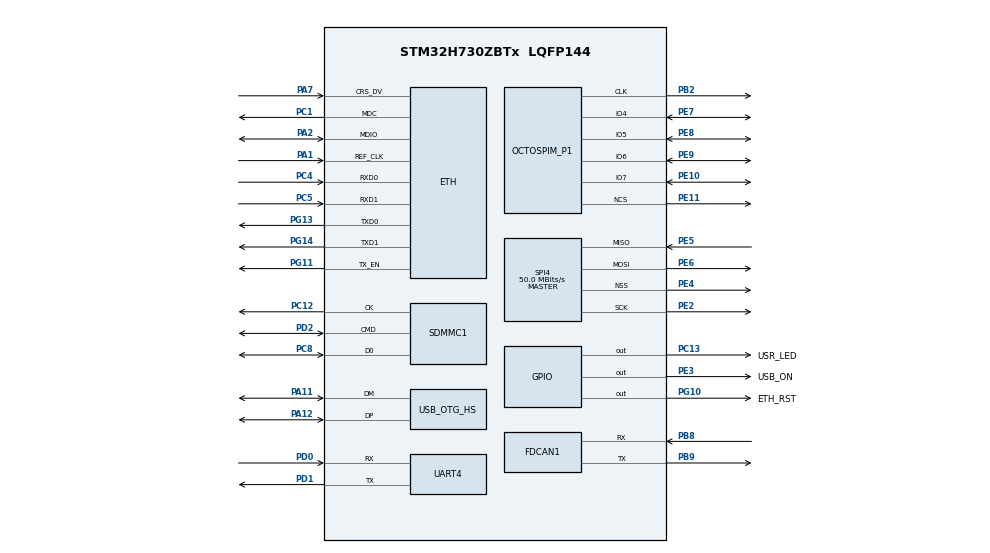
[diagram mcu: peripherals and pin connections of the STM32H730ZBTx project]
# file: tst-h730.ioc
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CORTEX_M7.CPU_DCache=Enabled
CORTEX_M7.CPU_ICache=Enabled
ETH.MediaInterface=HAL_ETH_RMII_MODE
FATFS._FS_NORTC=1
FATFS._FS_RPATH=2
FATFS._LFN_UNICODE=0
FATFS._MULTI_PARTITION=0
FATFS._USE_LABEL=0
FATFS._USE_LFN=1
LWIP.BSP.number=1
LWIP.LWIP_DBG_MIN_LEVEL=LWIP_DBG_MASK_LEVEL
LWIP.Version=v2.1.2_Cube
LWIP0.BSP.STBoard=false
LWIP0.BSP.api=BSP_COMPONENT_DRIVER
LWIP0.BSP.component=LAN8742
LWIP0.BSP.i2caddr=0
LWIP0.BSP.instance=LAN8742
LWIP0.BSP.name=Driver_PHY
LWIP0.BSP.solution=LAN8742
Mcu.Family=STM32H7
Mcu.Name=STM32H730ZBTx
Mcu.Package=LQFP144
NVIC.PriorityGroup=NVIC_PRIORITYGROUP_4
OCTOSPI1.ClockPrescaler=200
OCTOSPI1.DeviceSize=22
PA1.GPIO_Speed=GPIO_SPEED_FREQ_VERY_HIGH
PA1.Mode=RMII
PA1.Signal=ETH_REF_CLK
PA11.Mode=Device_Only_FS
PA11.Signal=USB_OTG_HS_DM
PA12.Mode=Device_Only_FS
PA12.Signal=USB_OTG_HS_DP
PA13(JTMS/SWDIO).Mode=Serial_Wire
PA13(JTMS/SWDIO).Signal=DEBUG_JTMS-SWDIO
PA14(JTCK/SWCLK).Mode=Serial_Wire
PA14(JTCK/SWCLK).Signal=DEBUG_JTCK-SWCLK
PA2.GPIO_Speed=GPIO_SPEED_FREQ_VERY_HIGH
PA2.Mode=RMII
PA2.Signal=ETH_MDIO
PA7.GPIO_Speed=GPIO_SPEED_FREQ_VERY_HIGH
PA7.Mode=RMII
PA7.Signal=ETH_CRS_DV
PB2.Mode=O1_P1_CLK
PB2.Signal=OCTOSPIM_P1_CLK
PB8.Mode=FDCAN_Activate
PB8.Signal=FDCAN1_RX
PB9.Mode=FDCAN_Activate
PB9.Signal=FDCAN1_TX
PC1.GPIO_Speed=GPIO_SPEED_FREQ_VERY_HIGH
PC1.Mode=RMII
PC1.Signal=ETH_MDC
PC12.Mode=SD_1_bit
PC12.Signal=SDMMC1_CK
PC13.GPIO_Label=USR_LED
PC13.Signal=GPIO_Output
PC4.GPIO_Speed=GPIO_SPEED_FREQ_VERY_HIGH
PC4.Mode=RMII
PC4.Signal=ETH_RXD0
PC5.GPIO_Speed=GPIO_SPEED_FREQ_VERY_HIGH
PC5.Mode=RMII
PC5.Signal=ETH_RXD1
PC8.Mode=SD_1_bit
PC8.Signal=SDMMC1_D0
PD0.Mode=Asynchronous
PD0.Signal=UART4_RX
PD1.Mode=Asynchronous
PD1.Signal=UART4_TX
PD2.Mode=SD_1_bit
PD2.Signal=SDMMC1_CMD
PE10.Mode=OCTOSPI1_IOL_Port1H
PE10.Signal=OCTOSPIM_P1_IO7
PE11.Mode=OCTOSPI1_Port1_NCS
PE11.Signal=OCTOSPIM_P1_NCS
PE2.Mode=Full_Duplex_Master
PE2.Signal=SPI4_SCK
PE3.GPIO_Label=USB_ON
PE3.PinState=GPIO_PIN_SET
PE3.Signal=GPIO_Output
PE4.Mode=NSS_Signal_Hard_Output
PE4.Signal=SPI4_NSS
PE5.Mode=Full_Duplex_Master
PE5.Signal=SPI4_MISO
PE6.Mode=Full_Duplex_Master
PE6.Signal=SPI4_MOSI
PE7.Mode=OCTOSPI1_IOL_Port1H
PE7.Signal=OCTOSPIM_P1_IO4
PE8.Mode=OCTOSPI1_IOL_Port1H
PE8.Signal=OCTOSPIM_P1_IO5
PE9.Mode=OCTOSPI1_IOL_Port1H
PE9.Signal=OCTOSPIM_P1_IO6
PG10.GPIO_Label=ETH_RST
PG10.GPIO_ModeDefaultOutputPP=GPIO_MODE_OUTPUT_OD
PG10.GPIO_PuPd=GPIO_PULLUP
PG10.PinState=GPIO_PIN_RESET
PG10.Signal=GPIO_Output
PG11.GPIO_Speed=GPIO_SPEED_FREQ_VERY_HIGH
PG11.Mode=RMII
PG11.Signal=ETH_TX_EN
PG13.GPIO_Speed=GPIO_SPEED_FREQ_VERY_HIGH
PG13.Mode=RMII
PG13.Signal=ETH_TXD0
PG14.GPIO_Speed=GPIO_SPEED_FREQ_VERY_HIGH
PG14.Mode=RMII
PG14.Signal=ETH_TXD1
PH0-OSC_IN.Mode=HSE-External-Oscillator
PH0-OSC_IN.Signal=RCC_OSC_IN
PH1-OSC_OUT.Mode=HSE-External-Oscillator
PH1-OSC_OUT.Signal=RCC_OSC_OUT
ProjectManager.HeapSize=0x200
ProjectManager.StackSize=0x400
ProjectManager.TargetToolchain=Makefile
RCC.ADCFreq_Value=200000000
RCC.APB1Freq_Value=137500000
RCC.APB2Freq_Value=137500000
RCC.APB3Freq_Value=137500000
RCC.APB4Freq_Value=137500000
RCC.CortexFreq_Value=550000000
RCC.D1PPRE=RCC_APB3_DIV2
RCC.D2PPRE1=RCC_APB1_DIV2
RCC.D2PPRE2=RCC_APB2_DIV2
RCC.D3PPRE=RCC_APB4_DIV2
RCC.DIVM1=4
RCC.DIVM2=4
RCC.DIVN1=275
RCC.DIVN2=200
RCC.DIVP1=1
RCC.DIVQ1=5
RCC.DIVQ2=4
RCC.DIVR1=10
RCC.FDCANCLockSelection=RCC_FDCANCLKSOURCE_PLL2
RCC.HCLKFreq_Value=275000000
RCC.HPRE=RCC_HCLK_DIV2
RCC.HSE_VALUE=8000000
RCC.LSE_Timout=50000
RCC.PLLSourceVirtual=RCC_PLLSOURCE_HSE
RCC.QSPICLockSelection=RCC_OSPICLKSOURCE_PLL2
RCC.SDMMC1CLockSelection=RCC_SDMMCCLKSOURCE_PLL2
RCC.SYSCLKFreq_VALUE=550000000
RCC.SYSCLKSource=RCC_SYSCLKSOURCE_PLLCLK
RCC.Spi45ClockSelection=RCC_SPI45CLKSOURCE_PLL2
RCC.SupplySource=PWR_LDO_SUPPLY
RCC.USART234578CLockSelection=RCC_USART234578CLKSOURCE_PLL2
RCC.USBCLockSelection=RCC_USBCLKSOURCE_HSI48
RCC.USBFreq_Value=48000000
SPI4.CalculateBaudRate=50.0 MBits/s
SPI4.Direction=SPI_DIRECTION_2LINES
SPI4.Mode=SPI_MODE_MASTER
SPI4.VirtualNSS=VM_NSSHARD
SPI4.VirtualType=VM_MASTER
USB_OTG_HS.VirtualMode=Device_Only_FS
VP_FATFS_VS_SDIO.Mode=SDIO
VP_LWIP_VS_Enabled.Mode=Enabled
VP_OCTOSPI1_VS_quad.Mode=quad_mode
VP_RCC_USB.Mode=USB_HS
VP_RNG_VS_RNG.Mode=RNG_Activate
VP_RTC_VS_RTC_Activate.Mode=RTC_Enabled
VP_RTC_VS_RTC_Calendar.Mode=RTC_Calendar
board=custom

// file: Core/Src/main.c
/* USER CODE BEGIN Header */
/**
  ******************************************************************************
  * @file           : main.c
  * @brief          : Main program body
  ******************************************************************************
  * @attention
  *
  * <h2><center>&copy; Copyright (c) 2021 STMicroelectronics.
  * All rights reserved.</center></h2>
  *
  * This software component is licensed by ST under BSD 3-Clause license,
  * the "License"; You may not use this file except in compliance with the
  * License. You may obtain a copy of the License at:
  *                        opensource.org/licenses/BSD-3-Clause
  *
  ******************************************************************************
  */
/* USER CODE END Header */
#include "main.h"
#include "fatfs.h"
#include "lwip.h"

/* USER CODE BEGIN Includes */
#include <app.h>
/* USER CODE END Includes */

FDCAN_HandleTypeDef hfdcan1;

OSPI_HandleTypeDef hospi1;

RNG_HandleTypeDef hrng;

RTC_HandleTypeDef hrtc;

SD_HandleTypeDef hsd1;

SPI_HandleTypeDef hspi4;

UART_HandleTypeDef huart4;

PCD_HandleTypeDef hpcd_USB_OTG_HS;

void SystemClock_Config(void);
void PeriphCommonClock_Config(void);
static void MX_GPIO_Init(void);
static void MX_FDCAN1_Init(void);
static void MX_OCTOSPI1_Init(void);
static void MX_RTC_Init(void);
static void MX_SDMMC1_SD_Init(void);
static void MX_SPI4_Init(void);
static void MX_UART4_Init(void);
static void MX_USB_OTG_HS_PCD_Init(void);
static void MX_RNG_Init(void);

int main(void)
{

  /* Enable I-Cache---------------------------------------------------------*/
  SCB_EnableICache();

  /* Enable D-Cache---------------------------------------------------------*/
  SCB_EnableDCache();

  /* MCU Configuration--------------------------------------------------------*/

  /* Reset of all peripherals, Initializes the Flash interface and the Systick. */
  HAL_Init();

  /* Configure the system clock */
  SystemClock_Config();

/* Configure the peripherals common clocks */
  PeriphCommonClock_Config();

  /* Initialize all configured peripherals */
  MX_GPIO_Init();
  MX_FDCAN1_Init();
  MX_OCTOSPI1_Init();
  MX_RTC_Init();
  MX_SDMMC1_SD_Init();
  MX_SPI4_Init();
  MX_UART4_Init();
  MX_USB_OTG_HS_PCD_Init();
  MX_FATFS_Init();
  MX_RNG_Init();
  MX_LWIP_Init();
  /* USER CODE BEGIN 2 */
  setup();
  /* USER CODE END 2 */

  /* Infinite loop */
  /* USER CODE BEGIN WHILE */
  while (1)
  {
    loop();
    /* USER CODE END WHILE */

    /* USER CODE BEGIN 3 */
    MX_LWIP_Process();
  }
  /* USER CODE END 3 */
}

void SystemClock_Config(void)
{
  RCC_OscInitTypeDef RCC_OscInitStruct = {0};
  RCC_ClkInitTypeDef RCC_ClkInitStruct = {0};
  RCC_CRSInitTypeDef RCC_CRSInitStruct = {0};

  /** Supply configuration update enable
  */
  HAL_PWREx_ConfigSupply(PWR_LDO_SUPPLY);
  /** Configure the main internal regulator output voltage
  */
  __HAL_PWR_VOLTAGESCALING_CONFIG(PWR_REGULATOR_VOLTAGE_SCALE0);

  while(!__HAL_PWR_GET_FLAG(PWR_FLAG_VOSRDY)) {}
  /** Macro to configure the PLL clock source
  */
  __HAL_RCC_PLL_PLLSOURCE_CONFIG(RCC_PLLSOURCE_HSE);
  /** Initializes the RCC Oscillators according to the specified parameters
  * in the RCC_OscInitTypeDef structure.
  */
  RCC_OscInitStruct.OscillatorType = RCC_OSCILLATORTYPE_HSI48|RCC_OSCILLATORTYPE_LSI
                              |RCC_OSCILLATORTYPE_HSE;
  RCC_OscInitStruct.HSEState = RCC_HSE_ON;
  RCC_OscInitStruct.LSIState = RCC_LSI_ON;
  RCC_OscInitStruct.HSI48State = RCC_HSI48_ON;
  RCC_OscInitStruct.PLL.PLLState = RCC_PLL_ON;
  RCC_OscInitStruct.PLL.PLLSource = RCC_PLLSOURCE_HSE;
  RCC_OscInitStruct.PLL.PLLM = 4;
  RCC_OscInitStruct.PLL.PLLN = 275;
  RCC_OscInitStruct.PLL.PLLP = 1;
  RCC_OscInitStruct.PLL.PLLQ = 5;
  RCC_OscInitStruct.PLL.PLLR = 10;
  RCC_OscInitStruct.PLL.PLLRGE = RCC_PLL1VCIRANGE_1;
  RCC_OscInitStruct.PLL.PLLVCOSEL = RCC_PLL1VCOWIDE;
  RCC_OscInitStruct.PLL.PLLFRACN = 0;
  if (HAL_RCC_OscConfig(&RCC_OscInitStruct) != HAL_OK)
  {
    Error_Handler();
  }
  /** Initializes the CPU, AHB and APB buses clocks
  */
  RCC_ClkInitStruct.ClockType = RCC_CLOCKTYPE_HCLK|RCC_CLOCKTYPE_SYSCLK
                              |RCC_CLOCKTYPE_PCLK1|RCC_CLOCKTYPE_PCLK2
                              |RCC_CLOCKTYPE_D3PCLK1|RCC_CLOCKTYPE_D1PCLK1;
  RCC_ClkInitStruct.SYSCLKSource = RCC_SYSCLKSOURCE_PLLCLK;
  RCC_ClkInitStruct.SYSCLKDivider = RCC_SYSCLK_DIV1;
  RCC_ClkInitStruct.AHBCLKDivider = RCC_HCLK_DIV2;
  RCC_ClkInitStruct.APB3CLKDivider = RCC_APB3_DIV2;
  RCC_ClkInitStruct.APB1CLKDivider = RCC_APB1_DIV2;
  RCC_ClkInitStruct.APB2CLKDivider = RCC_APB2_DIV2;
  RCC_ClkInitStruct.APB4CLKDivider = RCC_APB4_DIV2;

  if (HAL_RCC_ClockConfig(&RCC_ClkInitStruct, FLASH_LATENCY_3) != HAL_OK)
  {
    Error_Handler();
  }
  /** Enable the SYSCFG APB clock
  */
  __HAL_RCC_CRS_CLK_ENABLE();
  /** Configures CRS
  */
  RCC_CRSInitStruct.Prescaler = RCC_CRS_SYNC_DIV1;
  RCC_CRSInitStruct.Source = RCC_CRS_SYNC_SOURCE_USB2;
  RCC_CRSInitStruct.Polarity = RCC_CRS_SYNC_POLARITY_RISING;
  RCC_CRSInitStruct.ReloadValue = __HAL_RCC_CRS_RELOADVALUE_CALCULATE(48000000,1000);
  RCC_CRSInitStruct.ErrorLimitValue = 34;
  RCC_CRSInitStruct.HSI48CalibrationValue = 32;

  HAL_RCCEx_CRSConfig(&RCC_CRSInitStruct);
}

void PeriphCommonClock_Config(void)
{
  RCC_PeriphCLKInitTypeDef PeriphClkInitStruct = {0};

  /** Initializes the peripherals clock
  */
  PeriphClkInitStruct.PeriphClockSelection = RCC_PERIPHCLK_OSPI|RCC_PERIPHCLK_SDMMC
                              |RCC_PERIPHCLK_SPI4|RCC_PERIPHCLK_FDCAN
                              |RCC_PERIPHCLK_UART4;
  PeriphClkInitStruct.PLL2.PLL2M = 4;
  PeriphClkInitStruct.PLL2.PLL2N = 200;
  PeriphClkInitStruct.PLL2.PLL2P = 2;
  PeriphClkInitStruct.PLL2.PLL2Q = 4;
  PeriphClkInitStruct.PLL2.PLL2R = 2;
  PeriphClkInitStruct.PLL2.PLL2RGE = RCC_PLL2VCIRANGE_1;
  PeriphClkInitStruct.PLL2.PLL2VCOSEL = RCC_PLL2VCOWIDE;
  PeriphClkInitStruct.PLL2.PLL2FRACN = 0;
  PeriphClkInitStruct.OspiClockSelection = RCC_OSPICLKSOURCE_PLL2;
  PeriphClkInitStruct.SdmmcClockSelection = RCC_SDMMCCLKSOURCE_PLL2;
  PeriphClkInitStruct.Spi45ClockSelection = RCC_SPI45CLKSOURCE_PLL2;
  PeriphClkInitStruct.FdcanClockSelection = RCC_FDCANCLKSOURCE_PLL2;
  PeriphClkInitStruct.Usart234578ClockSelection = RCC_USART234578CLKSOURCE_PLL2;
  if (HAL_RCCEx_PeriphCLKConfig(&PeriphClkInitStruct) != HAL_OK)
  {
    Error_Handler();
  }
}

static void MX_FDCAN1_Init(void)
{

  hfdcan1.Instance = FDCAN1;
  hfdcan1.Init.FrameFormat = FDCAN_FRAME_CLASSIC;
  hfdcan1.Init.Mode = FDCAN_MODE_NORMAL;
  hfdcan1.Init.AutoRetransmission = DISABLE;
  hfdcan1.Init.TransmitPause = DISABLE;
  hfdcan1.Init.ProtocolException = DISABLE;
  hfdcan1.Init.NominalPrescaler = 1;
  hfdcan1.Init.NominalSyncJumpWidth = 1;
  hfdcan1.Init.NominalTimeSeg1 = 2;
  hfdcan1.Init.NominalTimeSeg2 = 2;
  hfdcan1.Init.DataPrescaler = 1;
  hfdcan1.Init.DataSyncJumpWidth = 1;
  hfdcan1.Init.DataTimeSeg1 = 1;
  hfdcan1.Init.DataTimeSeg2 = 1;
  hfdcan1.Init.MessageRAMOffset = 0;
  hfdcan1.Init.StdFiltersNbr = 0;
  hfdcan1.Init.ExtFiltersNbr = 0;
  hfdcan1.Init.RxFifo0ElmtsNbr = 0;
  hfdcan1.Init.RxFifo0ElmtSize = FDCAN_DATA_BYTES_8;
  hfdcan1.Init.RxFifo1ElmtsNbr = 0;
  hfdcan1.Init.RxFifo1ElmtSize = FDCAN_DATA_BYTES_8;
  hfdcan1.Init.RxBuffersNbr = 0;
  hfdcan1.Init.RxBufferSize = FDCAN_DATA_BYTES_8;
  hfdcan1.Init.TxEventsNbr = 0;
  hfdcan1.Init.TxBuffersNbr = 0;
  hfdcan1.Init.TxFifoQueueElmtsNbr = 0;
  hfdcan1.Init.TxFifoQueueMode = FDCAN_TX_FIFO_OPERATION;
  hfdcan1.Init.TxElmtSize = FDCAN_DATA_BYTES_8;
  if (HAL_FDCAN_Init(&hfdcan1) != HAL_OK)
  {
    Error_Handler();
  }

}

static void MX_OCTOSPI1_Init(void)
{

  OSPIM_CfgTypeDef sOspiManagerCfg = {0};

  /* OCTOSPI1 parameter configuration*/
  hospi1.Instance = OCTOSPI1;
  hospi1.Init.FifoThreshold = 1;
  hospi1.Init.DualQuad = HAL_OSPI_DUALQUAD_DISABLE;
  hospi1.Init.MemoryType = HAL_OSPI_MEMTYPE_MICRON;
  hospi1.Init.DeviceSize = 22;
  hospi1.Init.ChipSelectHighTime = 1;
  hospi1.Init.FreeRunningClock = HAL_OSPI_FREERUNCLK_DISABLE;
  hospi1.Init.ClockMode = HAL_OSPI_CLOCK_MODE_0;
  hospi1.Init.WrapSize = HAL_OSPI_WRAP_NOT_SUPPORTED;
  hospi1.Init.ClockPrescaler = 200;
  hospi1.Init.SampleShifting = HAL_OSPI_SAMPLE_SHIFTING_NONE;
  hospi1.Init.DelayHoldQuarterCycle = HAL_OSPI_DHQC_DISABLE;
  hospi1.Init.ChipSelectBoundary = 1;
  hospi1.Init.ClkChipSelectHighTime = 0;
  hospi1.Init.DelayBlockBypass = HAL_OSPI_DELAY_BLOCK_BYPASSED;
  hospi1.Init.MaxTran = 0;
  hospi1.Init.Refresh = 0;
  if (HAL_OSPI_Init(&hospi1) != HAL_OK)
  {
    Error_Handler();
  }
  sOspiManagerCfg.ClkPort = 1;
  sOspiManagerCfg.NCSPort = 1;
  sOspiManagerCfg.IOLowPort = HAL_OSPIM_IOPORT_1_HIGH;
  if (HAL_OSPIM_Config(&hospi1, &sOspiManagerCfg, HAL_OSPI_TIMEOUT_DEFAULT_VALUE) != HAL_OK)
  {
    Error_Handler();
  }

}

static void MX_RNG_Init(void)
{

  hrng.Instance = RNG;
  hrng.Init.ClockErrorDetection = RNG_CED_ENABLE;
  if (HAL_RNG_Init(&hrng) != HAL_OK)
  {
    Error_Handler();
  }

}

static void MX_RTC_Init(void)
{

  RTC_TimeTypeDef sTime = {0};
  RTC_DateTypeDef sDate = {0};

  /** Initialize RTC Only
  */
  hrtc.Instance = RTC;
  hrtc.Init.HourFormat = RTC_HOURFORMAT_24;
  hrtc.Init.AsynchPrediv = 127;
  hrtc.Init.SynchPrediv = 255;
  hrtc.Init.OutPut = RTC_OUTPUT_DISABLE;
  hrtc.Init.OutPutPolarity = RTC_OUTPUT_POLARITY_HIGH;
  hrtc.Init.OutPutType = RTC_OUTPUT_TYPE_OPENDRAIN;
  hrtc.Init.OutPutRemap = RTC_OUTPUT_REMAP_NONE;
  if (HAL_RTC_Init(&hrtc) != HAL_OK)
  {
    Error_Handler();
  }

  /** Initialize RTC and set the Time and Date
  */
  sTime.Hours = 0x0;
  sTime.Minutes = 0x0;
  sTime.Seconds = 0x0;
  sTime.DayLightSaving = RTC_DAYLIGHTSAVING_NONE;
  sTime.StoreOperation = RTC_STOREOPERATION_RESET;
  if (HAL_RTC_SetTime(&hrtc, &sTime, RTC_FORMAT_BCD) != HAL_OK)
  {
    Error_Handler();
  }
  sDate.WeekDay = RTC_WEEKDAY_MONDAY;
  sDate.Month = RTC_MONTH_JANUARY;
  sDate.Date = 0x1;
  sDate.Year = 0x0;

  if (HAL_RTC_SetDate(&hrtc, &sDate, RTC_FORMAT_BCD) != HAL_OK)
  {
    Error_Handler();
  }

}

static void MX_SDMMC1_SD_Init(void)
{

  hsd1.Instance = SDMMC1;
  hsd1.Init.ClockEdge = SDMMC_CLOCK_EDGE_RISING;
  hsd1.Init.ClockPowerSave = SDMMC_CLOCK_POWER_SAVE_DISABLE;
  hsd1.Init.BusWide = SDMMC_BUS_WIDE_1B;
  hsd1.Init.HardwareFlowControl = SDMMC_HARDWARE_FLOW_CONTROL_DISABLE;
  hsd1.Init.ClockDiv = 0;

}

static void MX_SPI4_Init(void)
{

  /* SPI4 parameter configuration*/
  hspi4.Instance = SPI4;
  hspi4.Init.Mode = SPI_MODE_MASTER;
  hspi4.Init.Direction = SPI_DIRECTION_2LINES;
  hspi4.Init.DataSize = SPI_DATASIZE_4BIT;
  hspi4.Init.CLKPolarity = SPI_POLARITY_LOW;
  hspi4.Init.CLKPhase = SPI_PHASE_1EDGE;
  hspi4.Init.NSS = SPI_NSS_HARD_OUTPUT;
  hspi4.Init.BaudRatePrescaler = SPI_BAUDRATEPRESCALER_2;
  hspi4.Init.FirstBit = SPI_FIRSTBIT_MSB;
  hspi4.Init.TIMode = SPI_TIMODE_DISABLE;
  hspi4.Init.CRCCalculation = SPI_CRCCALCULATION_DISABLE;
  hspi4.Init.CRCPolynomial = 0x0;
  hspi4.Init.NSSPMode = SPI_NSS_PULSE_ENABLE;
  hspi4.Init.NSSPolarity = SPI_NSS_POLARITY_LOW;
  hspi4.Init.FifoThreshold = SPI_FIFO_THRESHOLD_01DATA;
  hspi4.Init.TxCRCInitializationPattern = SPI_CRC_INITIALIZATION_ALL_ZERO_PATTERN;
  hspi4.Init.RxCRCInitializationPattern = SPI_CRC_INITIALIZATION_ALL_ZERO_PATTERN;
  hspi4.Init.MasterSSIdleness = SPI_MASTER_SS_IDLENESS_00CYCLE;
  hspi4.Init.MasterInterDataIdleness = SPI_MASTER_INTERDATA_IDLENESS_00CYCLE;
  hspi4.Init.MasterReceiverAutoSusp = SPI_MASTER_RX_AUTOSUSP_DISABLE;
  hspi4.Init.MasterKeepIOState = SPI_MASTER_KEEP_IO_STATE_DISABLE;
  hspi4.Init.IOSwap = SPI_IO_SWAP_DISABLE;
  if (HAL_SPI_Init(&hspi4) != HAL_OK)
  {
    Error_Handler();
  }

}

static void MX_UART4_Init(void)
{

  huart4.Instance = UART4;
  huart4.Init.BaudRate = 115200;
  huart4.Init.WordLength = UART_WORDLENGTH_8B;
  huart4.Init.StopBits = UART_STOPBITS_1;
  huart4.Init.Parity = UART_PARITY_NONE;
  huart4.Init.Mode = UART_MODE_TX_RX;
  huart4.Init.HwFlowCtl = UART_HWCONTROL_NONE;
  huart4.Init.OverSampling = UART_OVERSAMPLING_16;
  huart4.Init.OneBitSampling = UART_ONE_BIT_SAMPLE_DISABLE;
  huart4.Init.ClockPrescaler = UART_PRESCALER_DIV1;
  huart4.AdvancedInit.AdvFeatureInit = UART_ADVFEATURE_NO_INIT;
  if (HAL_UART_Init(&huart4) != HAL_OK)
  {
    Error_Handler();
  }
  if (HAL_UARTEx_SetTxFifoThreshold(&huart4, UART_TXFIFO_THRESHOLD_1_8) != HAL_OK)
  {
    Error_Handler();
  }
  if (HAL_UARTEx_SetRxFifoThreshold(&huart4, UART_RXFIFO_THRESHOLD_1_8) != HAL_OK)
  {
    Error_Handler();
  }
  if (HAL_UARTEx_DisableFifoMode(&huart4) != HAL_OK)
  {
    Error_Handler();
  }

}

static void MX_USB_OTG_HS_PCD_Init(void)
{

  hpcd_USB_OTG_HS.Instance = USB_OTG_HS;
  hpcd_USB_OTG_HS.Init.dev_endpoints = 9;
  hpcd_USB_OTG_HS.Init.speed = PCD_SPEED_FULL;
  hpcd_USB_OTG_HS.Init.dma_enable = DISABLE;
  hpcd_USB_OTG_HS.Init.phy_itface = USB_OTG_EMBEDDED_PHY;
  hpcd_USB_OTG_HS.Init.Sof_enable = DISABLE;
  hpcd_USB_OTG_HS.Init.low_power_enable = DISABLE;
  hpcd_USB_OTG_HS.Init.lpm_enable = DISABLE;
  hpcd_USB_OTG_HS.Init.battery_charging_enable = ENABLE;
  hpcd_USB_OTG_HS.Init.vbus_sensing_enable = DISABLE;
  hpcd_USB_OTG_HS.Init.use_dedicated_ep1 = DISABLE;
  hpcd_USB_OTG_HS.Init.use_external_vbus = DISABLE;
  if (HAL_PCD_Init(&hpcd_USB_OTG_HS) != HAL_OK)
  {
    Error_Handler();
  }

}

static void MX_GPIO_Init(void)
{
  GPIO_InitTypeDef GPIO_InitStruct = {0};

  /* GPIO Ports Clock Enable */
  __HAL_RCC_GPIOE_CLK_ENABLE();
  __HAL_RCC_GPIOC_CLK_ENABLE();
  __HAL_RCC_GPIOH_CLK_ENABLE();
  __HAL_RCC_GPIOA_CLK_ENABLE();
  __HAL_RCC_GPIOB_CLK_ENABLE();
  __HAL_RCC_GPIOD_CLK_ENABLE();
  __HAL_RCC_GPIOG_CLK_ENABLE();

  /*Configure GPIO pin Output Level */
  HAL_GPIO_WritePin(USB_ON_GPIO_Port, USB_ON_Pin, GPIO_PIN_SET);

  /*Configure GPIO pin Output Level */
  HAL_GPIO_WritePin(USR_LED_GPIO_Port, USR_LED_Pin, GPIO_PIN_RESET);

  /*Configure GPIO pin Output Level */
  HAL_GPIO_WritePin(ETH_RST_GPIO_Port, ETH_RST_Pin, GPIO_PIN_RESET);

  /*Configure GPIO pin : USB_ON_Pin */
  GPIO_InitStruct.Pin = USB_ON_Pin;
  GPIO_InitStruct.Mode = GPIO_MODE_OUTPUT_PP;
  GPIO_InitStruct.Pull = GPIO_NOPULL;
  GPIO_InitStruct.Speed = GPIO_SPEED_FREQ_LOW;
  HAL_GPIO_Init(USB_ON_GPIO_Port, &GPIO_InitStruct);

  /*Configure GPIO pin : USR_LED_Pin */
  GPIO_InitStruct.Pin = USR_LED_Pin;
  GPIO_InitStruct.Mode = GPIO_MODE_OUTPUT_PP;
  GPIO_InitStruct.Pull = GPIO_NOPULL;
  GPIO_InitStruct.Speed = GPIO_SPEED_FREQ_LOW;
  HAL_GPIO_Init(USR_LED_GPIO_Port, &GPIO_InitStruct);

  /*Configure GPIO pin : ETH_RST_Pin */
  GPIO_InitStruct.Pin = ETH_RST_Pin;
  GPIO_InitStruct.Mode = GPIO_MODE_OUTPUT_OD;
  GPIO_InitStruct.Pull = GPIO_PULLUP;
  GPIO_InitStruct.Speed = GPIO_SPEED_FREQ_LOW;
  HAL_GPIO_Init(ETH_RST_GPIO_Port, &GPIO_InitStruct);

  /*Configure GPIO pin : PG15 */
  GPIO_InitStruct.Pin = GPIO_PIN_15;
  GPIO_InitStruct.Mode = GPIO_MODE_AF_PP;
  GPIO_InitStruct.Pull = GPIO_NOPULL;
  GPIO_InitStruct.Speed = GPIO_SPEED_FREQ_VERY_HIGH;
  GPIO_InitStruct.Alternate = GPIO_AF9_OCTOSPIM_P2;
  HAL_GPIO_Init(GPIOG, &GPIO_InitStruct);

}

void Error_Handler(void)
{
  __disable_irq();
  while (1)
  {
  }
}

/************************ (C) COPYRIGHT STMicroelectronics *****END OF FILE****/
